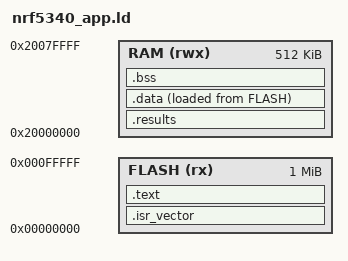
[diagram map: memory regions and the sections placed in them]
/* nRF5340 application core: 1 MB flash, 512 KB RAM. */
MEMORY
{
    FLASH (rx)  : ORIGIN = 0x00000000, LENGTH = 1024K
    RAM   (rwx) : ORIGIN = 0x20000000, LENGTH = 512K
}

ENTRY(Reset_Handler)
_estack = ORIGIN(RAM) + LENGTH(RAM);

SECTIONS
{
    .isr_vector : { KEEP(*(.isr_vector)) } > FLASH
    .text : { *(.text*) *(.rodata*) . = ALIGN(4); } > FLASH

    /* Results first in RAM, at a fixed address the host reads. */
    .results (NOLOAD) : { KEEP(*(.results)) . = ALIGN(4); } > RAM

    .data : {
        _sdata = .;
        *(.data*)
        . = ALIGN(4);
        _edata = .;
    } > RAM AT > FLASH
    _sidata = LOADADDR(.data);

    .bss (NOLOAD) : {
        _sbss = .;
        *(.bss*) *(COMMON)
        . = ALIGN(4);
        _ebss = .;
    } > RAM
}
